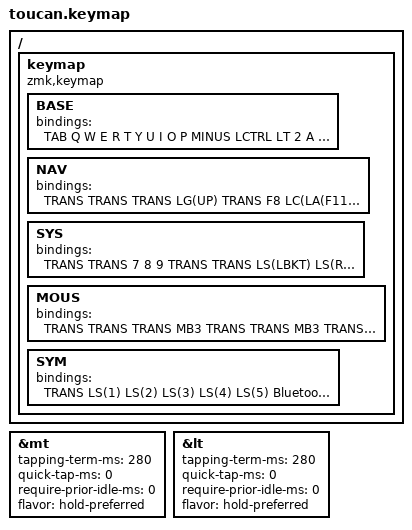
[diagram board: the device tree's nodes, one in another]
&mt {
    tapping-term-ms = <280>;
    quick-tap-ms = <0>;
    require-prior-idle-ms = <0>;
    flavor = "hold-preferred";
};
&lt {
    tapping-term-ms = <280>;
    quick-tap-ms = <0>;
    require-prior-idle-ms = <0>;
    flavor = "hold-preferred";
};

/ {
  keymap {
    compatible = "zmk,keymap";

    BASE {
      bindings = <
        TAB
        Q
        W
        E
        R
        T
        Y
        U
        I
        O
        P
        MINUS
        LCTRL
        LT 2 A
        S
        D
        F
        G
        H
        J
        K
        LT 3 L
        SEMI
        MT RCTRL TAB
        MT LSHIFT LANG2
        MT LSHIFT Z
        X
        C
        V
        B
        N
        M
        COMMA
        LT 2 DOT
        MT RSHIFT SLASH
        MT LSHIFT LANG1
        LT 4 LGUI
        LT 1 SPACE
        MT LCTRL ESC
        BSPC
        LT 2 ENTER
        MT RALT ENTER
      >;
    };

    NAV {
      bindings = <
        TRANS
        TRANS
        TRANS
        LG(UP)
        TRANS
        F8
        LC(LA(F11))
        HOME
        UP
        END
        GRAVE
        TRANS
        TRANS
        LCTRL
        LS(LG(LEFT))
        LG(DOWN)
        LS(LG(RIGHT))
        TRANS
        PGUP
        LEFT
        DOWN
        RIGHT
        PGDN
        TRANS
        TRANS
        LSHIFT
        F2
        F3
        F4
        F5
        F9
        F10
        F11
        F12
        TRANS
        TRANS
        TRANS
        TRANS
        TRANS
        TRANS
        TRANS
        TRANS
      >;
    };

    SYS {
      bindings = <
        TRANS
        TRANS
        7
        8
        9
        TRANS
        TRANS
        LS(LBKT)
        LS(RBKT)
        LS(LG(S))
        PRSC
        TRANS
        TRANS
        TRANS
        4
        5
        6
        TRANS
        LG(TAB)
        LS(9)
        LS(0)
        TRANS
        BSLH
        TRANS
        Studio Unlock
        TRANS
        1
        2
        3
        TRANS
        TRANS
        LBKT
        RBKT
        TRANS
        SEMI
        TRANS
        TRANS
        0
        TRANS
        DEL
        TRANS
        TRANS
      >;
    };

    MOUS {
      bindings = <
        TRANS
        TRANS
        TRANS
        MB3
        TRANS
        TRANS
        MB3
        TRANS
        TRANS
        TRANS
        TRANS
        TRANS
        TRANS
        TRANS
        TRANS
        MB2
        MB1
        TRANS
        MB2
        MB4
        MB5
        TRANS
        TRANS
        TRANS
        TRANS
        TRANS
        TRANS
        LC(C)
        LC(V)
        TRANS
        MO Layer 1
        TRANS
        TRANS
        TRANS
        TRANS
        TRANS
        TRANS
        TRANS
        TRANS
        MB1
        TRANS
        TRANS
      >;
    };

    SYM {
      bindings = <
        TRANS
        LS(1)
        LS(2)
        LS(3)
        LS(4)
        LS(5)
        Bluetooth 3
        TRANS
        TRANS
        TRANS
        MINUS
        TRANS
        TRANS
        LCTRL
        LS(6)
        LS(8)
        LS(7)
        LS(BSLH)
        Bluetooth 3 1
        TRANS
        TRANS
        TRANS
        EQUAL
        TRANS
        TRANS
        LSHIFT
        SEMI
        LS(SEMI)
        LS(SQT)
        SQT
        Bluetooth 3 2
        TRANS
        TRANS
        TRANS
        TRANS
        Bluetooth Clear Selected Profile
        TRANS
        TRANS
        TRANS
        DEL
        TRANS
        TRANS
      >;
    };
  };
};
